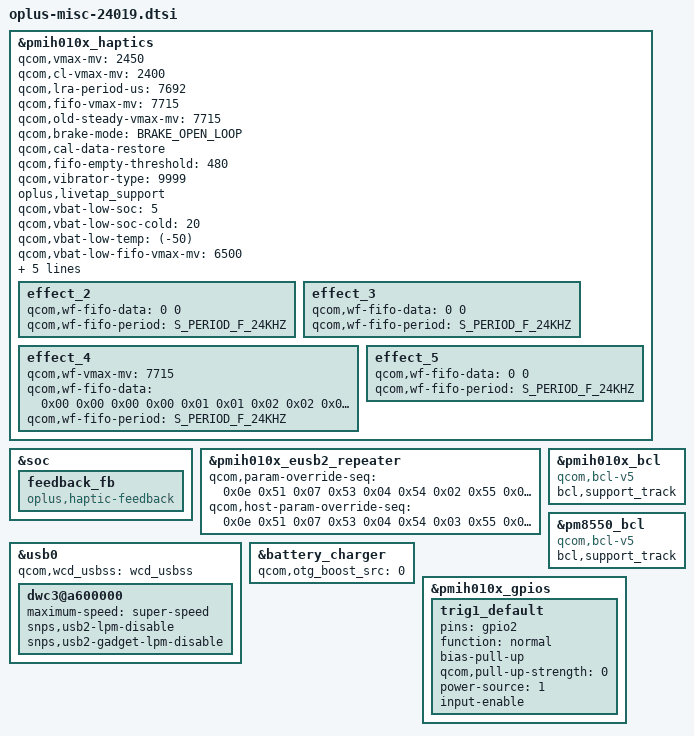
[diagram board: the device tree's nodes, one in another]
&pmih010x_haptics {
	qcom,vmax-mv = <2450>;
	qcom,cl-vmax-mv = <2400>;
	qcom,lra-period-us = <7692>;
	qcom,fifo-vmax-mv = <7715>;
	qcom,old-steady-vmax-mv = <7715>;
	qcom,brake-mode = <BRAKE_OPEN_LOOP>;
	qcom,cal-data-restore;
	qcom,fifo-empty-threshold = <480>;
	qcom,vibrator-type = <9999>;//zhangheng
	oplus,livetap_support;
	qcom,vbat-low-soc = <5>;
	qcom,vbat-low-soc-cold = <20>;
	qcom,vbat-low-temp = <(-50)>;/*-5C*/
	qcom,vbat-low-fifo-vmax-mv = <6500>;
	qcom,hbst-ovp-trim;
	oplus,trig_support;
	interrupt-parent = <&spmi_bus>;
	oplus,trig1-gpio = <&pmih010x_gpios 2 GPIO_ACTIVE_LOW>;
	pinctrl-names = "default";
	pinctrl-0 = <&trig1_default>;
	/delete-node/ effect_0;
	/delete-node/ effect_1;
	/delete-node/ primitive_0;
	/delete-node/ primitive_1;
	/delete-node/ primitive_2;
	/delete-node/ primitive_3;
	/delete-node/ primitive_4;
	/delete-node/ primitive_5;
	/delete-node/ primitive_6;
	/delete-node/ primitive_7;
	/delete-node/ primitive_8;
	effect_2 { /* trig3 */
		qcom,wf-fifo-data = /bits/ 8 <0 0>;
		qcom,wf-fifo-period = <S_PERIOD_F_24KHZ>;
	};
	effect_3 { /* trig2 */
		qcom,wf-fifo-data = /bits/ 8 <0 0>;
		qcom,wf-fifo-period = <S_PERIOD_F_24KHZ>;
	};
	effect_4 { /* trig1 */
		qcom,wf-vmax-mv = <7715>;
		qcom,wf-fifo-data = /bits/ 8 <0x00 0x00 0x00 0x00 0x01 0x01 0x02 0x02 0x03 0x04
			0x04 0x05 0x06 0x08 0x08 0x0a 0x0c 0x0e 0x10 0x12
			0x15 0x18 0x1b 0x1e 0x21 0x25 0x28 0x2c 0x30 0x33
			0x37 0x3b 0x3f 0x43 0x48 0x4b 0x4f 0x53 0x56 0x59
			0x5c 0x5e 0x60 0x62 0x64 0x66 0x67 0x68 0x69 0x69
			0x69 0x68 0x68 0x67 0x66 0x64 0x61 0x5f 0x5c 0x59
			0x55 0x51 0x4c 0x47 0x41 0x3b 0x35 0x2e 0x27 0x20
			0x18 0x10 0x08 0x00 0xf8 0xf0 0xe9 0xe1 0xd9 0xd2
			0xcc 0xc5 0xbf 0xb9 0xb4 0xb0 0xac 0xa8 0xa5 0xa2
			0xa0 0x9e 0x9d 0x9c 0x9c 0x9c 0x9d 0x9e 0x9f 0xa1
			0xa4 0xa6 0xaa 0xae 0xb2 0xb7 0xbc 0xc2 0xc8 0xce
			0xd5 0xdd 0xe4 0xec 0xf4 0xfc 0x03 0x0b 0x13 0x1b
			0x23 0x2a 0x31 0x37 0x3d 0x43 0x48 0x4d 0x51 0x56
			0x59 0x5b 0x5e 0x5f 0x61 0x62 0x62 0x62 0x61 0x60
			0x5e 0x5c 0x58 0x55 0x51 0x4c 0x47 0x42 0x3b 0x36
			0x2f 0x27 0x1f 0x17 0x0f 0x07 0xff 0xf7 0xef 0xe8
			0xe1 0xdb 0xd4 0xcf 0xca 0xc7 0xc4 0xc1 0xbf 0xbd
			0xbd 0xbd 0xbd 0xbe 0xc0 0xc2 0xc4 0xc6 0xc9 0xcc
			0xcd 0xd0 0xd3 0xd6 0xd8 0xdb 0xdd 0xdf 0xe1 0xe4
			0xe5 0xe7 0xe8 0xea 0xec 0xed 0xed 0xef 0xf0 0xf1
			0xf1 0xf1 0xf2 0xf3 0xf3 0xf4 0xf4 0xf5 0xf5 0xf6
			0xf6 0xf6 0xf6 0xf6 0xf6 0xf6 0xf7 0xf7 0xf7 0xf7
			0xf7 0xf8 0xf8 0xf8 0xf8 0xf8 0xf8 0xf9 0xf9 0xf9
			0xf9 0xf9 0xf9 0xf9 0xf9 0xf9 0xf9 0xfa 0xfa 0xfa
			0xfa 0xfa 0xfa 0xfa 0xfa 0xfa 0xfa 0xfb 0xfb 0xfb
			0xfb 0xfb 0xfb 0xfb 0xfb 0xfb 0xfb 0xfb 0xfb 0xfb
			0xfb 0xfb 0xfb 0xfb 0xfb 0xfb 0xfb 0xfb 0xfb 0xfb
			0xfb 0xfb 0xfb 0xfb 0xfc 0xfc 0xfc 0xfc 0xfc 0xfc
			0xfc 0xfc 0xfc 0xfc 0xfc 0xfc 0xfc 0xfc 0xfc 0xfc
			0xfc 0xfd 0xfd 0xfd 0xfd 0xfd 0xfd 0xfd 0xfd 0xfd
			0xfd 0xfd 0xfd 0xfd 0xfd 0xfd 0xfd 0xfd 0xfd 0xfd
			0xfd 0xfd 0xfd 0xfd 0xfd 0xfe 0xfe 0xfe 0xfe 0xfe
			0xfe 0xfe 0xfe 0xfe 0xfe 0xfe 0xfe 0xfe 0xfe 0xfe
			0xfe 0xfe 0xfe 0xfe 0xfe 0xfe 0xfe 0xfe 0xfe 0xfe
			0xfe 0xfe 0xfe 0xfe 0xfe 0xfe 0xfe 0xfe 0xff 0xff
			0xff 0xff 0xff 0xff 0xff 0xff 0xff 0xff 0xff 0xff
			0xff 0xff 0xff 0xff 0xff 0xff 0xff 0xff 0xff 0xff
			0xff 0xff 0xff 0xff 0xff 0xff 0xff 0xff 0xff 0xff
			0xff 0xff 0xff 0xff 0xff 0xff 0xff 0xff 0xff 0xff
			0xff 0xff 0xff>;
		qcom,wf-fifo-period = <S_PERIOD_F_24KHZ>;
	};
	effect_5 {
		qcom,wf-fifo-data = /bits/ 8 <0 0>;
		qcom,wf-fifo-period = <S_PERIOD_F_24KHZ>;
	};
};

&soc {
	feedback_fb: feedback_fb {
		compatible = "oplus,haptic-feedback";
	};
};

&pmih010x_eusb2_repeater {
	qcom,param-override-seq = <0x0e 0x51 0x07 0x53 0x04 0x54 0x02 0x55 0x04 0x57>;
	qcom,host-param-override-seq = <0x0e 0x51 0x07 0x53 0x04 0x54 0x03 0x55 0x03 0x57>;
};

&usb0 {
	qcom,wcd_usbss = <&wcd_usbss>;
	dwc3@a600000 {
		maximum-speed = "super-speed";
		snps,usb2-lpm-disable;
		snps,usb2-gadget-lpm-disable;
	};
};

&battery_charger {
        qcom,otg_boost_src = <0>; /* 0:plat_pmic 1:external */
};

&pmih010x_bcl {
	compatible = "qcom,bcl-v5";
	bcl,support_track;
};

&pm8550_bcl {
	compatible = "qcom,bcl-v5";
	bcl,support_track;
};

&pmih010x_gpios {
	trig1_default: trig1_default {
		pins = "gpio2"; /* GPIO 2 */
		function = "normal"; /* normal input */
		bias-pull-up; /* enable pull up */
		qcom,pull-up-strength = <0>; /* 30uA pull up */
		power-source = <1>; /* VIN0 */
		input-enable; /* digital input */
	};
};
